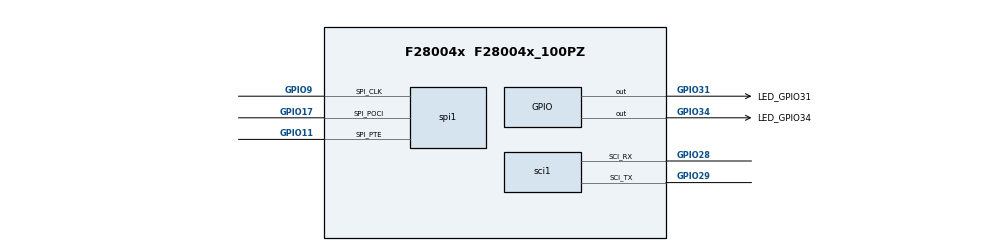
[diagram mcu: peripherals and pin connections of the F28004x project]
/**
 * @cliArgs --device "F28004x" --package "F28004x_100PZ" --part "F28004x_100PZ" --context "system" --product "C2000WARE@5.01.00.00"
 * @versions {"tool":"1.17.0+3128"}
 */

/**
 * Import the modules used in this configuration.
 */
const cputimer  = scripting.addModule("/driverlib/cputimer.js", {}, false);
const cputimer1 = cputimer.addInstance();
const epwm      = scripting.addModule("/driverlib/epwm.js", {}, false);
const epwm1     = epwm.addInstance();
const gpio      = scripting.addModule("/driverlib/gpio.js", {}, false);
const gpio1     = gpio.addInstance();
const gpio2     = gpio.addInstance();
const sci       = scripting.addModule("/driverlib/sci.js", {}, false);
const sci1      = sci.addInstance();
const spi       = scripting.addModule("/driverlib/spi.js", {}, false);
const spi1      = spi.addInstance();

/**
 * Write custom configuration values to the imported modules.
 */
cputimer1.$name          = "SWTIRMER";
cputimer1.timerPrescaler = 2;
cputimer1.startTimer     = true;
cputimer1.timerPeriod    = 50000000;

epwm1.$name = "BUCK_PWM1";

gpio1.$name           = "LED_GPIO34";
gpio1.direction       = "GPIO_DIR_MODE_OUT";
gpio1.gpioPin.$assign = "GPIO34";

gpio2.$name           = "LED_GPIO31";
gpio2.direction       = "GPIO_DIR_MODE_OUT";
gpio2.gpioPin.$assign = "GPIO31";

sci1.$name                 = "DEBUG_SCI";
sci1.parity                = "SCI_CONFIG_PAR_EVEN";
sci1.sci.sci_rxPin.$assign = "GPIO28";
sci1.sci.sci_txPin.$assign = "GPIO29";

spi1.$name                   = "SPIA_SLAVE";
spi1.emulationMode           = "SPI_EMULATION_FREE_RUN";
spi1.bitRate                 = 1000000;
spi1.useInterrupts           = false;
spi1.spi.spi_pociPin.$assign = "GPIO17";
spi1.spi.spi_clkPin.$assign  = "GPIO9";
spi1.spi.spi_ptePin.$assign  = "GPIO11";

/**
 * Pinmux solution for unlocked pins/peripherals. This ensures that minor changes to the automatic solver in a future
 * version of the tool will not impact the pinmux you originally saw.  These lines can be completely deleted in order to
 * re-solve from scratch.
 */
epwm1.epwm.$suggestSolution           = "EPWM1";
epwm1.epwm.epwm_aPin.$suggestSolution = "GPIO0";
epwm1.epwm.epwm_bPin.$suggestSolution = "GPIO1";
sci1.sci.$suggestSolution             = "SCIA";
spi1.spi.$suggestSolution             = "SPIA";
spi1.spi.spi_picoPin.$suggestSolution = "GPIO16";
